# CC27x0 register map
File version: 1.0
CPU: CM4 r0p4, little endian, no MPU, no FPU, VTOR, 3 interrupt priority bits
Registers are 32-bit, read-write, reset 0x0 unless marked. A register's access mark holds for its fields unless they carry their own. Offsets are from the block's base; [hi:lo] are bit positions.

## DCB
Base 0xE000EDE0
0x10 DHCSR — Controls halting debug
  [26] S_RESTART_ST ro — Indicates the PE has processed a request to clear DHCSR.C_HALT to 0. That is, either a write to DHCSR that clears DHCSR.C_HALT from 1 to 0, or an External Restart Request
  [25] S_RESET_ST ro — Indicates whether the PE has been reset since the last read of the DHCSR
  [24] S_RETIRE_ST ro — Set to 1 every time the PE retires one of more instructions
  [23:21] RES0_1 ro — Reserved, RES0
  [20] S_SDE ro — Indicates whether Secure invasive debug is allowed
  [19] S_LOCKUP ro — Indicates whether the PE is in Lockup state
  [18] S_SLEEP ro — Indicates whether the PE is sleeping
  [17] S_HALT ro — Indicates whether the PE is in Debug state
  [31:16] DBGKEY wo — A debugger must write 0xA05F to this field to enable write access to the remaining bits, otherwise the PE ignores the write access
  [16] S_REGRDY ro — Handshake flag to transfers through the DCRDR
  [15:6] RES0_2 ro — Reserved, RES0
  [5] C_SNAPSTALL — Allow imprecise entry to Debug state
  [4] RES0_3 ro — Reserved, RES0
  [3] C_MASKINTS — When debug is enabled, the debugger can write to this bit to mask PendSV, SysTick and external configurable interrupts
  [2] C_STEP — Enable single instruction step
  [1] C_HALT — PE enter Debug state halt request
  [0] C_DEBUGEN — Enable Halting debug
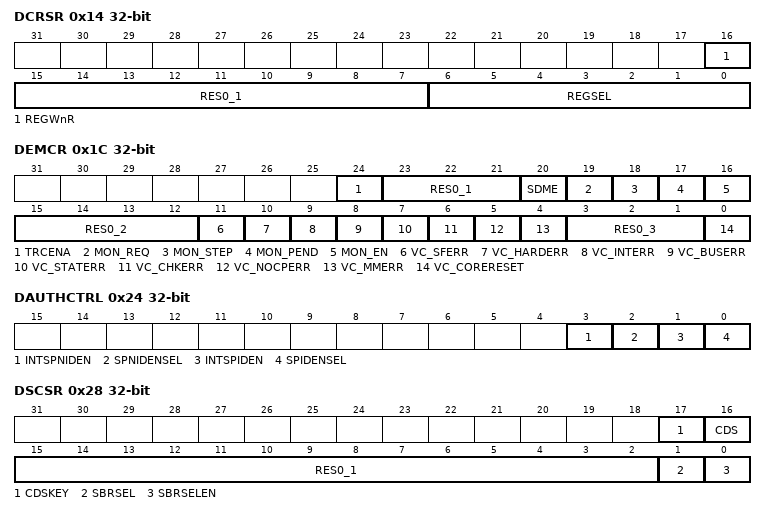
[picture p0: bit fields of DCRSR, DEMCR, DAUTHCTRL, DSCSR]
0x14 DCRSR — With the DCRDR, provides debug access to the general-purpose registers, special-purpose registers, and the FP extension registers. A write to the DCRSR specifies the register to transfer, whether the transfer is a read or write, and starts the transfer
  [16] REGWnR wo — Specifies the access type for the transfer
  [15:7] RES0_1 ro — Reserved, RES0
  [6:0] REGSEL wo — Specifies the general-purpose register, special-purpose register, or FP register to transfer
0x18 DCRDR — With the DCRSR, provides debug access to the general-purpose registers, special-purpose registers, and the FP Extension registers. If the Main Extension is implemented, it can also be used for message passing between an external debugger and a debug agent running on the PE
  [31:0] DBGTMP — Provides debug access for reading and writing the general-purpose registers, special-purpose registers, and Floating-point Extension registers
0x1C DEMCR — Manages vector catch behavior and DebugMonitor handling when debugging
  [24] TRCENA — Global enable for all DWT and ITM features
  [23:21] RES0_1 ro — Reserved, RES0
  [20] SDME ro — Indicates whether the DebugMonitor targets the Secure or the Non-secure state and whether debug events are allowed in Secure state
  [19] MON_REQ — DebugMonitor semaphore bit
  [18] MON_STEP — Enable DebugMonitor stepping
  [17] MON_PEND — Sets or clears the pending state of the DebugMonitor exception
  [16] MON_EN — Enable the DebugMonitor exception
  [15:12] RES0_2 ro — Reserved, RES0
  [11] VC_SFERR — SecureFault exception halting debug vector catch enable
  [10] VC_HARDERR — HardFault exception halting debug vector catch enable
  [9] VC_INTERR — Enable halting debug vector catch for faults during exception entry and return
  [8] VC_BUSERR — BusFault exception halting debug vector catch enable
  [7] VC_STATERR — Enable halting debug trap on a UsageFault exception caused by a state information error, for example an Undefined Instruction exception
  [6] VC_CHKERR — Enable halting debug trap on a UsageFault exception caused by a checking error, for example an alignment check error
  [5] VC_NOCPERR — Enable halting debug trap on a UsageFault caused by an access to a coprocessor
  [4] VC_MMERR — Enable halting debug trap on a MemManage exception
  [3:1] RES0_3 ro — Reserved, RES0
  [0] VC_CORERESET — Enable Reset Vector Catch. This causes a warm reset to halt a running system
0x24 DAUTHCTRL — This register allows the external authentication interface to be overridden from software.
  [3] INTSPNIDEN — Internal Secure non-invasive debug enable. Overrides the external Secure non-invasive debug authentication interface
  [2] SPNIDENSEL — Secure non-invasive debug enable select. Selects between DAUTHCTRL and the external authentication interface for control of Secure non-invasive debug
  [1] INTSPIDEN — Internal Secure invasive debug enable. Overrides the external Secure invasive debug authentication Interfaces.
  [0] SPIDENSEL — Secure invasive debug enable select. Selects between DAUTHCTRL and the external authentication interface for control of Secure invasive debug.
0x28 DSCSR — Provides control and status information for Secure debug
  [17] CDSKEY — Writes to the CDS bit are ignored unless CDSKEY is concurrently written to zero
  [16] CDS — This field indicates the current Security state of the processor
  [15:2] RES0_1 ro — Reserved, RES0
  [1] SBRSEL — If SBRSELEN is 1 this bit selects whether the Non-secure or the Secure version of the memory-mapped Banked registers are accessible to the debugger
  [0] SBRSELEN — Controls whether the SBRSEL field or the current Security state of the processor selects which version of the memory-mapped Banked registers are accessed to the debugger
